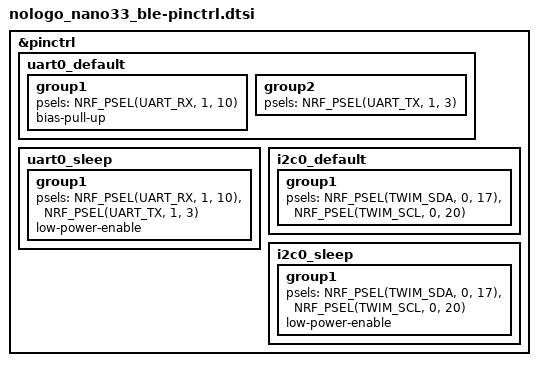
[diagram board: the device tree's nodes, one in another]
/*
 * Copyright (c) 2022 The ZMK Contributors
 * SPDX-License-Identifier: MIT
 */

&pinctrl {
    uart0_default: uart0_default {
        group1 {
            psels = <NRF_PSEL(UART_RX, 1, 10)>;
            bias-pull-up;
        };
        group2 {
            psels = <NRF_PSEL(UART_TX, 1, 3)>;
        };
    };

    uart0_sleep: uart0_sleep {
        group1 {
            psels = <NRF_PSEL(UART_RX, 1, 10)>,
                <NRF_PSEL(UART_TX, 1, 3)>;
            low-power-enable;
        };
    };

    i2c0_default: i2c0_default {
        group1 {
            psels = <NRF_PSEL(TWIM_SDA, 0, 17)>,
                <NRF_PSEL(TWIM_SCL, 0, 20)>;
        };
    };

    i2c0_sleep: i2c0_sleep {
        group1 {
            psels = <NRF_PSEL(TWIM_SDA, 0, 17)>,
                <NRF_PSEL(TWIM_SCL, 0, 20)>;
            low-power-enable;
        };
    };
};
